# cslr_srio register map
Vendor: Texas Instruments
Peripheral module from a debugger description file (folder TCI6484_C6457).
Registers are 32-bit, access not given, reset 0x0 unless marked. A register's access mark holds for its fields unless they carry their own. Offsets are as the file gives them; lines under a group give offsets from that group; [hi:lo] are bit positions; {n}, {i} and the like mark numbered series; 'fields as' and 'values as' point back to an identical list; <NAME> marks a mode.

## SRIO (part 1 of 2) — Rapid input/output
{0x0+0x10*i} TX_BUFF_DESC[{i}] (i=0..31) group — TX buffer descriptors
  0x00 TXnextDescPtr rw — Transfer buffer descriptor 0
    [31:0] NEXT_DESC — Next Descriptor Pointer - The 32-bit word aligned memory address of the next buffer descriptor in the TX queue. This is the mechanism used to reference the next buffer descriptor from the current buffer descriptor. If the value of this pointer is zero then the current buffer is the last buffer in the queue.
  0x04 TXbuffPtr rw — Transmit buffer descriptor 1
    [31:0] BUFFER_POINTER — Buffer Pointer - The byte aligned memory address of the buffer associated with the buffer descriptor.
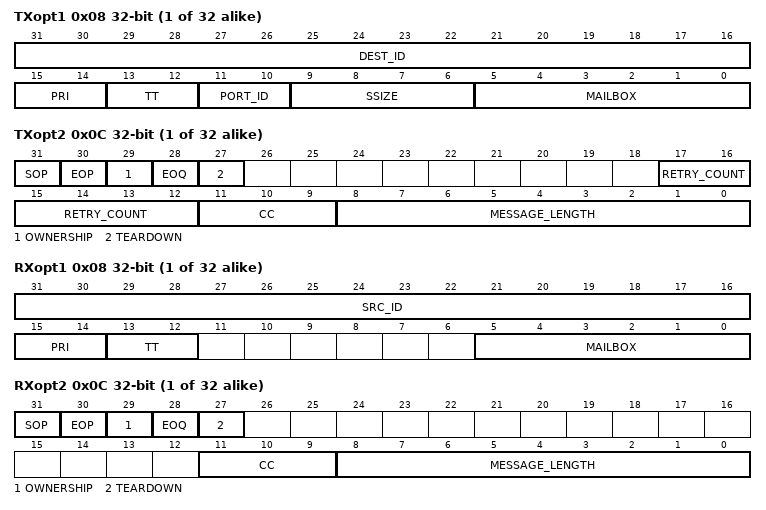
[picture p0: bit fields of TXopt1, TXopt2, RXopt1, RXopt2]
  0x08 TXopt1 rw — Transmit buffer descriptor 2
    [31:16] DEST_ID — Destination Node Id  Unique Node identifier for the Destination of the message
    [15:14] PRI — Message Priority  Specifies the SRIO priority at which the message will be sent. Messages should not be sent at a priority level of 3 since the message response is required to promote the priority to avoid system deadlock. It is the responsibility of the software to assign the appropriate out-going priority
    [13:12] TT — RapidIO tt field specifying 8 or 16bit DeviceIDs
    [11:10] PORT_ID — Port number for routing outgoing packet.
    [9:6] SSIZE — RIO standard message payload size. Indicates how the hardware should segment the out-going message by specifying the maximum number of double-words per packet
    [5:0] MAILBOX — Destination Mailbox  Specifies the mailbox to which the message will be sent.
  0x0C TXopt2 — Transmit buffer descriptor 3
    [31] SOP rw — Start of Message - Indicates that the descriptor buffer is the first buffer in the message
    [30] EOP rw — End of Message - Indicates that the descriptor buffer is the last buffer in the message
    [29] OWNERSHIP rw — Ownership - Indicates ownership of the message and is valid only on sop. This bit is set by the host and cleared by the port when the message has been transmitted. The host uses this bit to reclaim buffers
    [28] EOQ rw — End Of Queue - Set by the port to indicate that all messages in the queue have been transmitted and the TX queue is empty. End of queue is determined by the port when the next_descriptor_pointer is zero on an eop buffer. This bit is valid only on eop
    [27] TEARDOWN rw — Teardown Complete  Set by the port to indicate that the host commanded teardown process is complete, and the channel buffers may be reclaimed by the host.
    [17:12] RETRY_COUNT rw — Message Retry Count  Set by the cpu to indicate the total number of retries allowed for this message, including all segments. Decremented by the port each time a message is retried
    [11:9] CC rw — Completion Code
    [8:0] MESSAGE_LENGTH rw — Message Length  Written by the CPU to specify the number of double-words to transmit. Message payloads are limited to a maximum size of 512 double-words (4096bytes).
{0x0+0x10*i} RX_BUFF_DESC[{i}] (i=0..31) group — RX buffer descriptors
  0x00 RXnextDescPtr rw — Receive buffer descriptor 0
    [31:0] NEXT_DESC — Next Descriptor Pointer - The 32-bit word aligned memory address of the next buffer descriptor in the RX queue. This is the mechanism used to reference the next buffer descriptor from the current buffer descriptor. If the value of this pointer is zero then the current buffer is the last buffer in the queue.
  0x04 RXbuffPtr rw — Receive buffer descriptor 1
    fields as TX_BUFF_DESC[0].TXbuffPtr
  0x08 RXopt1 — Receive buffer descriptor 2
    [31:16] SRC_ID rw — Source Node Id  Unique Node identifier for the Source of the message
    [15:14] PRI rw — Message Priority  Specifies the SRIO priority at which the message will be sent. Messages should not be sent at a priority level of 3 since the message response is required to promote the priority to avoid system deadlock. It is the responsibility of the software to assign the appropriate out-going priority
    [13:12] TT rw — RapidIO tt field specifying 8 or 16bit DeviceIDs
    [5:0] MAILBOX rw — Destination Mailbox  Specifies the mailbox to which the message was sent.
  0x0C RXopt2 — Receive buffer descriptor 3
    [31] SOP rw — Start of Message - Indicates that the descriptor buffer is the first buffer in the message
    [30] EOP rw — End of Message - Indicates that the descriptor buffer is the last buffer in the message
    [29] OWNERSHIP rw — Ownership - Indicates ownership of the message and is valid only on "sop". This bit is set by the host and cleared by the port when the message has been transmitted. The host uses this bit to reclaim buffers
    [28] EOQ rw — End Of Queue - Set by the port to indicate that the RX queue empty condition exists. This bit is valid only on "eop". The port determines the end of queue condition by a zero next_descriptor_pointer
    [27] TEARDOWN rw — Teardown Complete  Set by the port to indicate that the host commanded teardown process is complete, and the channel buffers may be reclaimed by the host.
    [11:9] CC rw — Completion Code
    [8:0] MESSAGE_LENGTH rw — Message Length  Written by the CPU to specify the number of double-words to transmit. Message payloads are limited to a maximum size of 512 double-words (4096bytes).
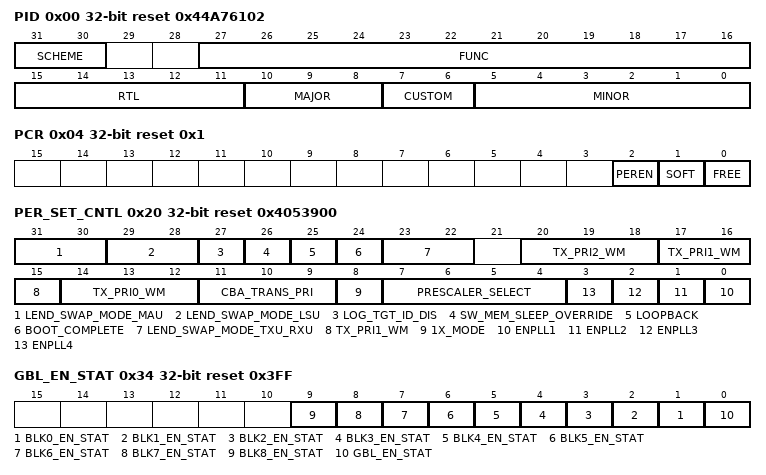
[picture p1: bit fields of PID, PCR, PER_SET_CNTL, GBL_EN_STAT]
0x00 PID reset 0x44A76102 — Peripheral Identification Register
  [31:30] SCHEME ro, [27:16] FUNC ro, [15:11] RTL ro, [10:8] MAJOR ro, [7:6] CUSTOM ro, [5:0] MINOR ro
0x04 PCR reset 0x1 — Peripheral Control register
  [2] PEREN rw — Peripheral Enable. Control the flow of data in the logical layer of the peripheral. As an initiator, it will prevent TX transaction generation and as a target, it will disable incoming requests. This should be the last enable bit to toggle when bringing the device out of reset to begin normal operation
    0=DISABLE (Disables data flow control); 1=ENABLE (Enables data flow control)
  [1] SOFT rw — Emulation Control  SOFT bit
  [0] FREE rw — Emulation Control  FREE bit
0x20 PER_SET_CNTL reset 0x4053900 — Peripheral Settings Control register
  [31:30] LEND_SWAP_MODE_MAU rw — MAU little-endian swapping mode
    0=MODE_A (MAU little-endian swapping mode); 1=MODE_B (MAU little-endian swapping mode); 2=MODE_C (MAU little-endian swapping mode); 3=MODE_D (MAU little-endian swapping mode)
  [29:28] LEND_SWAP_MODE_LSU rw — LSU little-endian swapping mode
    0=MODE_A (LSU little-endian swapping mode); 1=MODE_B (LSU little-endian swapping mode); 2=MODE_C (LSU little-endian swapping mode); 3=MODE_D (LSU little-endian swapping mode)
  [27] LOG_TGT_ID_DIS rw — Logical layer disable. This bit disables all the packet types at the logical layer.
    0=DESTROY_PACKETS (All non-matching packets are destroyed.); 1=FORWARD_PACKETS (All packets, regardless of the destination ID, are forwarded to the application.)
  [26] SW_MEM_SLEEP_OVERRIDE rw — Software Memory Sleep Override 0b0  While in shutdown, memories are put in sleep mode 0b1  While in shutdown, memories are not put in sleep mode
    0=DISABLE; 1=ENABLE (Memories are not put in sleep mode)
  [25] LOOPBACK rw — Loopback mode. 0b: Normal operation 1b: Loop back. Trasmit data to receive on the same port.Packet data is looped back in the digital domain before the SerDes macros
    0=DISABLE (Normal operation); 1=ENABLE (Loop back mode)
  [24] BOOT_COMPLETE rw — Controls ability to write any register during initialization. It also includes read only registers during normal mode of operation, that have application defined reset value. 0  write enabled 1 - write to read only registers disabled Usually the boot_complete is asserted once after reset to define power on configuration
    0=WRITE_ENABLE (Write to read only registers enabled); 1=WRITE_DISABLE (Write to read only registers disabled)
  [23:22] LEND_SWAP_MODE_TXU_RXU rw — TXU/RXU little-endian swapping mode
    0=MODE_A; 1=MODE_B; 2=MODE_C; 3=MODE_D
  [20:18] TX_PRI2_WM rw — Transmit credit threshold. Sets the required number of logical layer TX buffers needed to send prority 2 packets across the UDI interface. This is valid for all ports in 1X mode only
  [17:15] TX_PRI1_WM rw — Transmit credit threshold. Sets the required number of logical layer TX buffers needed to send prority 1 packets across the UDI interface. This is valid for all ports in 1X mode only
  [14:12] TX_PRI0_WM rw — Transmit credit threshold. Sets the required number of logical layer TX buffers needed to send prority 0 packets across the UDI interface. This is valid for all ports in 1X mode only
  [11:9] CBA_TRANS_PRI rw — VBUS transaction priority. 0b000  Highest Priority, 0b111  Lowest Priority.
  [8] 1X_MODE rw — This register bit determines the UDI buffering setup(Prority versus Port).
    0=DISABLE (UDI buffers are priority based); 1=ENABLE (UDI buffers are port based. This mode must be selected when using more than one 1X port)
  [7:4] PRESCALER_SELECT rw — Internal frequency prescaler, used to drive the request to response timers. These 4 bits are the prescaler reload value allowing division of the VBUS clock by a range from 1 up to 16. Setting should reflect the device VBUS frequency.
  [n-1] ENPLL{n} rw (n=1..4) — Drives SerDes Macro {n} PLL Enable signal
0x30 GBL_EN — Peripheral Global Enable register
  [0] EN rw — Controls reset to all clock domains within the peripheral
    0=DISABLE (Peripheral to be disabled (held in reset, clocks disabled)); 1=ENABLE (Peripheral to be enabled)
0x34 GBL_EN_STAT reset 0x3FF — Peripheral Global Enable Status
  [n+1] BLK{n}_EN_STAT ro (n=0..8) — Indicates state of BLK{n}_EN reset signal
  [0] GBL_EN_STAT ro — Indicates state of GBL_EN reset signal
{0x38+8i} BLK{i}_EN reset 0x1 (i=0..8) — Block Enable
  [0] EN rw — Controls reset to Logical block n (0 to 8)
    0=DISABLE (Logical block n disabled); 1=ENABLE (Logical block n enabled)
{0x3C+8i} BLK{i}_EN_STAT reset 0x1 (i=0..8) — Block Enable Status
  [0] EN_STAT rw — Indicates state of BLKn_EN reset signal 0 Logical block n disabled, in reset and clock is off 1 Logical block n enabled and clocking
    values as BLK0_EN.EN
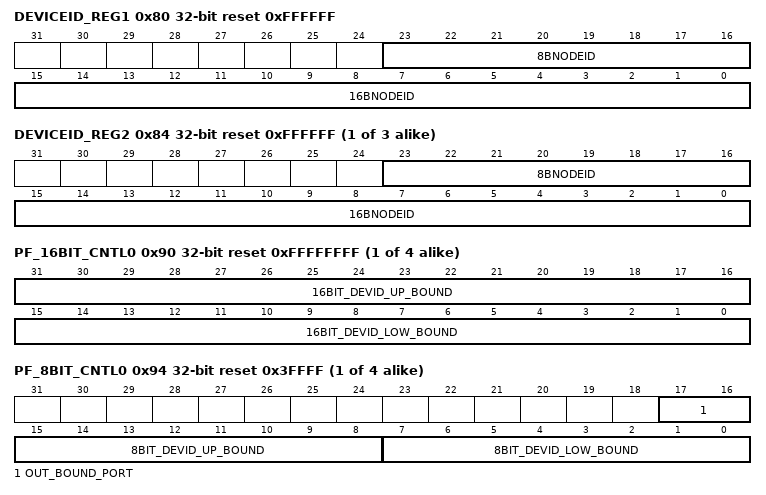
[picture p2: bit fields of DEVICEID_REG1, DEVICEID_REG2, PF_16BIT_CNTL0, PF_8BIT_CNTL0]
0x80 DEVICEID_REG1 reset 0xFFFFFF — RapidIO DEVICEID1 Register
  [23:16] 8BNODEID rw — This value is equal to the value of the RapidIO Base Device ID CSR. The CPU must read the CSR value and set this register, so that out-going packets contain the correct SOURCEID value
  [15:0] 16BNODEID rw — This value is equal to the value of the RapidIO Base Device ID CSR. The CPU must read the CSR value and set this register, so that out-going packets contain the correct SOURCEID value
{0x7C+4i} DEVICEID_REG{i} reset 0xFFFFFF (i=2..4) — RapidIO DEVICEID{i} Register
  [23:16] 8BNODEID rw — This is a secondary supported DeviceID checked against an in-coming packet's DestID field. Typically used for Multi-cast support
  [15:0] 16BNODEID rw — This is a secondary supported DeviceID checked against an in-coming packet's DestID field. Typically used for Multi-cast support
{0x90+8i} PF_16BIT_CNTL{i} rw reset 0xFFFFFFFF (i=0..3) — Packet Forwarding register for 16b DeviceIDs
  [31:16] 16BIT_DEVID_UP_BOUND — Upper 16b DeviceID boundary. DestID above this range cannot use the table entry
  [15:0] 16BIT_DEVID_LOW_BOUND — Lower 16b DeviceID boundary. DestID lower than this number cannot use the table entry
{0x94+8i} PF_8BIT_CNTL{i} reset 0x3FFFF (i=0..3) — Packet Forwarding register for 8b DeviceIDs
  [17:16] OUT_BOUND_PORT rw — Output port number for packet's whose DestID falls within the 8b or 16b range for this table entry
  [15:8] 8BIT_DEVID_UP_BOUND rw — Upper 8b DeviceID boundary. DestID above this range cannot use the table entry
  [7:0] 8BIT_DEVID_LOW_BOUND rw — Lower 8b DeviceID boundary. DestID lower than this number cannot use the table entry
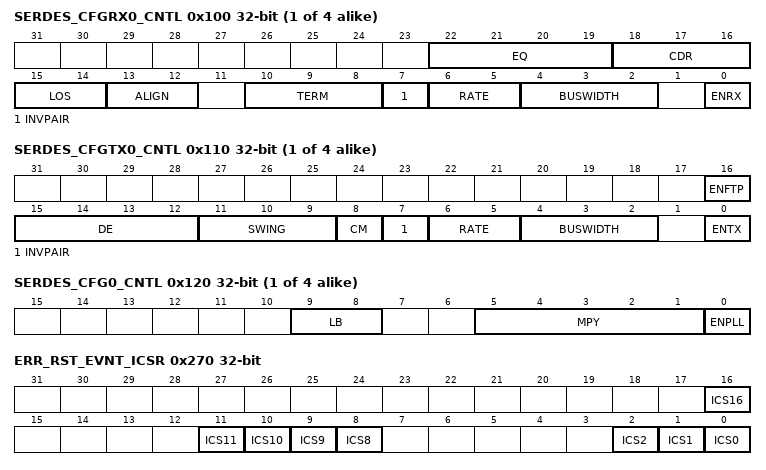
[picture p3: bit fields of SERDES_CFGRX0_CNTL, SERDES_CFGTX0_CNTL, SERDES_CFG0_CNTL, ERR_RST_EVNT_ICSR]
{0x100+4i} SERDES_CFGRX{i}_CNTL (i=0..3) — SerDes RX Channels CFG register
  [22:19] EQ rw — Equalizer. Enables and configures the adaptive equalizer to compensate for loss in the transmission media.
  [18:16] CDR rw — Clock/data recovery. Configures the clock/data recovery algorithm.
  [15:14] LOS rw — Loss of signal. Enables loss of signal detection with 2 selectable thresholds.
  [13:12] ALIGN rw — Symbol alignment. Enables internal or external symbol alignment.
  [10:8] TERM rw — Termination. Selects input termination options suitable for a variety of AC or DC coupled scenarios.
  [7] INVPAIR rw — Invert polarity. Inverts polarity of RXPi and RXNi.
  [6:5] RATE rw — Operating rate. Selects full, half, quarter rate operation
  [4:2] BUSWIDTH rw — Bus width. Selects the parallel interface width (10 or 8 bit).
  [0] ENRX rw — Receive enable.
{0x110+4i} SERDES_CFGTX{i}_CNTL (i=0..3) — SerDes TX Channels CFG register
  [16] ENFTP rw — Enable fixed TXBCLKINn phase.
  [15:12] DE rw — De-emphasis. Selects one of 15 output de-emphasis settings from 4.76% to 71.42%.
  [11:9] SWING rw — Output swing. Selects one of 8 output amplitude settings between 125 and 1250mVdfpp.
  [8] CM rw — Common mode. Adjusts the common mode to suit the termination at the attached receiver.
  [7] INVPAIR rw — Invert polarity. Inverts polarity of TXPn and TXNn.
  [6:5] RATE rw — Operating rate. Selects full, half, quarter rate operation
  [4:2] BUSWIDTH rw — Bus width. Selects the parallel interface width (10 or 8 bit).
  [0] ENTX rw — Trasmit enable.
{0x120+4i} SERDES_CFG{i}_CNTL (i=0..3) — SerDes Macros CFG register
  [9:8] LB rw — Loop Bandwidth. Specify loop bandwidth settings.
  [5:1] MPY rw — PLL multiply. Select PLL Multiply factors between 4 and 60.
  [0] ENPLL rw — Enable PLL. Enables the PLL.
{0x200+0x10*i} DOORBELL_ICSR{i} (i=0..3) — DOORBELL Interrupt Status register
  [15:0] ICS[16] rw — Doorbell n (0 to 3) interrupt condition status bits
{0x208+0x10*i} DOORBELL_ICCR{i} (i=0..3) — DOORBELL Interrupt Clear register
  [15:0] ICC[16] wo — Doorbell n (0 to 3) interrupt clear bits
    1=CLEAR
0x240 RX_CPPI_ICSR — RX CPPI Interrupt Status register
  [15:0] ICS[16] rw — RX CPPI Interrupt, Buffer descriptor Queue 0 to 15
0x248 RX_CPPI_ICCR — RX CPPI Interrupt Clear register
  [15:0] ICC[16] wo — RX CPPI Interrupt clear, Buffer descriptor Queue 0 to 15
    1=CLEAR
0x250 TX_CPPI_ICSR — TX CPPI Interrupt Status register
  [15:0] ICS[16] rw — TX CPPI Interrupt, Buffer descriptor Queue 0 to 15
0x258 TX_CPPI_ICCR — TX CPPI Interrupt Clear register
  [15:0] ICC[16] wo — TX CPPI Interrupt clear, Buffer descriptor Queue 0 to 15
    1=CLEAR
0x260 LSU_ICSR ro — LSU Status Interrupt register
  [31:0] ICS[32] — Load/Store module interrupt condition status bits
0x268 LSU _ICCR wo — LSU Clear Interrupt register
  [31:0] ICC[32] — Load/Store module interrupt clear bits
    1=CLEAR
0x270 ERR_RST_EVNT_ICSR — Error, Reset, and Special Event Status Interrupt register
  [16] ICS16 ro — Device Reset Interrupt from any port
  [n] ICS{n} ro (n=8..11) — Port{n-8} Error
  [2] ICS2 ro — Logical Layer Error Management Event Capture
  [1] ICS1 ro — Port-write-In request received on any port
  [0] ICS0 ro — Multi-cast event control symbol interrupt received on any port
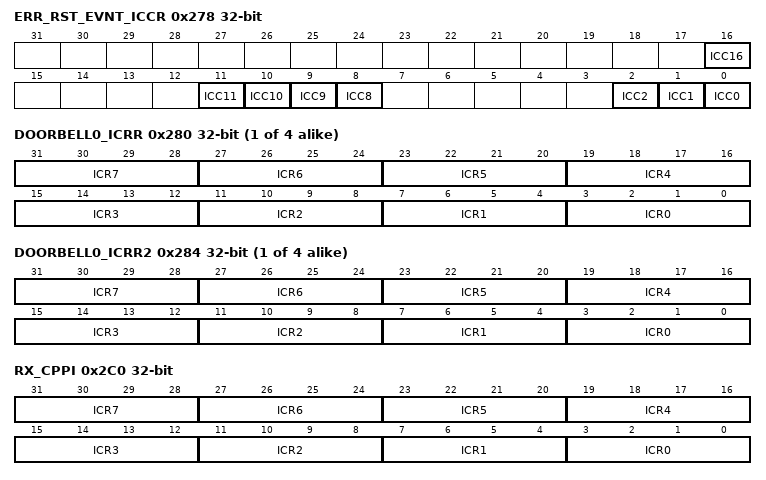
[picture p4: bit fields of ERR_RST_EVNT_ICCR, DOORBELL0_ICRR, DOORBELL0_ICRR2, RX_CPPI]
0x278 ERR_RST_EVNT_ICCR — Error, Reset, and Special Event Clear Interrupt register
  [16] ICC16 wo — Device Reset Interrupt from any port
  [n] ICC{n} wo (n=8..11) — Port{n-8} Error
  [2] ICC2 wo — Logical Layer Error Management Event Capture
  [1] ICC1 wo — Port-write-In request received on any port
  [0] ICC0 wo — Multi-cast event control symbol interrupt received on any port
{0x280+0x10*i} DOORBELL{i}_ICRR rw (i=0..3) — DOORBELL Interrupt Condition Routing register (bits 0 to 7)
  [4n+3:4n] ICR{n} (n=0..7)
{0x284+0x10*i} DOORBELL{i}_ICRR2 rw (i=0..3) — DOORBELL Interrupt Condition Routing register (bits 8 to 15)
  [4n+3:4n] ICR{n} (n=0..7)
0x2C0 RX_CPPI _ICRR rw — RX CPPI Interrupt Condition Routing register (bits 0 to 7)
  [4n+3:4n] ICR{n} (n=0..7)
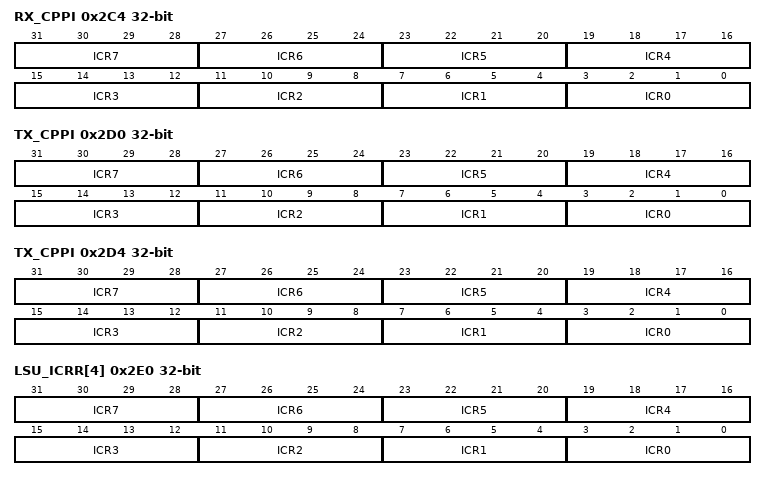
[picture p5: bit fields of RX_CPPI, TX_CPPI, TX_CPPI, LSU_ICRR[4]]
0x2C4 RX_CPPI _ICRR2 rw — RX CPPI Interrupt Condition Routing register (bits 8 to 15)
  [4n+3:4n] ICR{n} (n=0..7)
0x2D0 TX_CPPI _ICRR rw — TX CPPI Interrupt Condition Routing register (bits 0 to 7)
  [4n+3:4n] ICR{n} (n=0..7)
0x2D4 TX_CPPI _ICRR2 rw — TX CPPI Interrupt Condition Routing register (bits 8 to 15)
  [4n+3:4n] ICR{n} (n=0..7)
0x2E0 LSU_ICRR[4] rw — LSU Module Interrupt Condition Routing register
  [4n+3:4n] ICR{n} (n=0..7)
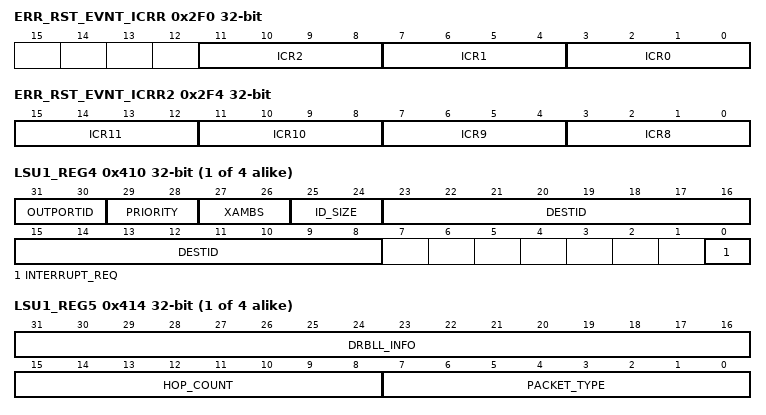
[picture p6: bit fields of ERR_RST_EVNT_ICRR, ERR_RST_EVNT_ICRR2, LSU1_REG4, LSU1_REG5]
0x2F0 ERR_RST_EVNT_ICRR — Err/Reset/special event Interrupt Condition Routing register
  [11:8] ICR2 rw — Logical Layer Error Management Event Capture routing
  [7:4] ICR1 rw — Routing of Port-write-In request received on any port
  [3:0] ICR0 rw — Routing of Multi-cast event control symbol interrupt received on any port
0x2F4 ERR_RST_EVNT_ICRR2 — Err/Reset/special event Interrupt Condition Routing register
  [4n-29:4n-32] ICR{n} rw (n=8..11) — Port{n-8} Error routing
0x2F8 ERR_RST_EVNT_ICRR3 — Err/Reset/special event Interrupt Condition Routing register
  [3:0] ICR16 rw — Routing of Device Reset Interrupt from any port
0x300 INTDST_DECODE[8] ro — INTDST Interrupt Status Decode registers
  [31:0] ISDR[32] — Interrupt sources that select a particular physical interrupt destination, are mapped to specific bits in the decode register. The interrupt sources are mapped to an interrupt decode register, only if the ICRR routes the interrupt source to the corresponding physical interrupt. The status decode bit is a logical "OR" of multiple interrupt sources that are mapped to the same bit.
0x320 INTDST_RATE_CNTL[8] rw — INTDST Interrupt Rate Control registers
  [31:0] COUNT_DOWN_VALUE — The rate at which an interrupt can be generated is controllable for each physical interrupt destination. Rate control is implemented with a programmable down-counter. The counter re-loads and immediately starts down-counting each time the CPU writes these registers. Once the rate control counter register is written, and the counter value reaches zero (note the CPU may write zero immediately for a zero count), the interrupt pulse generation logic is allowed to fire a single pulse if any bits in the corresponding ICSR register bits are set (or become set after the zero count is reached). .
{0x3E0+0x20*i} LSU{i}_REG0 rw (i=1..4) — LSU Control register0
  [31:0] ADDRESS_MSB — 32 bit Ext address fields
{0x3E4+0x20*i} LSU{i}_REG1 rw (i=1..4) — LSU Control register1
  [31:0] ADDRESS_LSB_CONFIG_OFFSET — 1) 32b Address  Packet Types 2,5, and 6 (Will be used in conjunction with BYTE_COUNT to create 64b aligned RapidIO packet header address) 2) 24b Config_offset Field  Maintenance Packets Type 8 (Will be used in conjunction with BYTE_COUNT to create 64b aligned RapidIO packet header Config_offset); The 2 lsb of this field must be zero since the smallest configuration access is 4B.
{0x3E8+0x20*i} LSU{i}_REG2 rw (i=1..4) — LSU Control register2
  [31:0] DSP_ADDRESS — 32b DSP byte address
{0x3EC+0x20*i} LSU{i}_REG3 (i=1..4) — LSU Control register3
  [11:0] BYTE_COUNT rw — Number of data bytes to Read/Write - up to 4KB. (Used in conjunction with RapidIO address to create WRSIZE/RDSIZE and WDPTR in RapidIO packet header).
{0x3F0+0x20*i} LSU{i}_REG4 (i=1..4) — LSU Control register4
  [31:30] OUTPORTID rw — Not applicable for Rapid IO header. Indicates the output port number for the packet to be transmitted from. Specified by the CPU along with NodeID.
  [29:28] PRIORITY rw — RapidIO prio field specifying packet priority. Request packets should not be sent at a priority level of 3 in order to avoid system deadlock. It is the responsibility of the software to assign the appropriate out-going priority.
  [27:26] XAMBS rw — RapidIO xambs field specifying extended address MSB
  [25:24] ID_SIZE rw — RapidIO tt field specifying 8 or 16bit DeviceIDs
    0=8BIT (8 bit device Ids); 1=16BIT (16 bit device Ids)
  [23:8] DESTID rw — RapidIO destinationID field specifying target device
  [0] INTERRUPT_REQ rw — CPU controlled request bit used for interrupt generation. Typically used in conjunction with non-posted commands to alert the CPU when the requested data/status is present. 0b0 - An interrupt is not requested upon completion of command 0b1- An interrupt is requested upon completion of command
    0=DISABLE (Interrupt is not requested); 1=ENABLE (Interrupt is requested)
{0x3F4+0x20*i} LSU{i}_REG5 rw (i=1..4) — LSU Control register5
  [31:16] DRBLL_INFO — RapidIO doorbell info field for type 10 packets
  [15:8] HOP_COUNT — RapidIO hop_count field specified for Type 8 Maintenance packets
  [7:0] PACKET_TYPE — 4 msb = 4b ftype field for all packets and 4 lsb = 4b trans field for Packet types 2,5,8
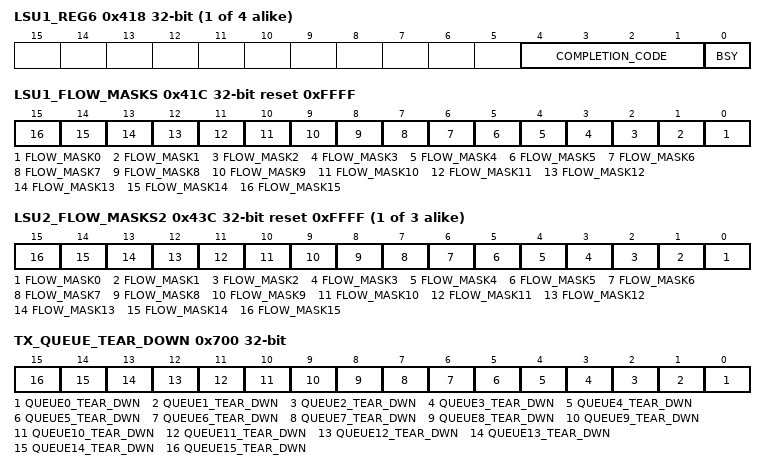
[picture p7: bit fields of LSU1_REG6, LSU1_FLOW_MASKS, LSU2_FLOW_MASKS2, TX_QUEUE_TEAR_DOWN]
{0x3F8+0x20*i} LSU{i}_REG6 (i=1..4) — LSU Control register6
  [4:1] COMPLETION_CODE ro — Indicates the status of the pending command 0b000  Transaction complete, No Errors (Posted/Non-posted) 0b001  Transaction Timeout occurred on Non-posted transaction 0b010  Transaction complete, Packet not sent due to flow control blockade (Xoff) 0b011  Transaction complete, Non-posted response packet (type 8 and 13) contained ERROR status, or response payload length was in error 0b100  Transaction complete, Packet not sent due to unsupported transaction type or invalid programming encoding for one or more LSU register fields 0b101  DMA data transfer error 0b110  "Retry" DOORBELL response received, or Atomic Test-and-swap was not allowed (semaphore in use) 0b111  Transaction complete, Packet not sent due to unavailable outbound credit at given priority
  [0] BSY ro — Indicates status of the command registers 0b0 - Command registers are available(writable) for next set of transfer descriptors 0b1 - Command registers are busy with current transfer
0x41C LSU1_FLOW_MASKS reset 0xFFFF — Core n LSU Congestion Control Flow Mask
  [n] FLOW_MASK{n} rw (n=0..15)
{0x3FC+0x20*i} LSU{i}_FLOW_MASKS{i} reset 0xFFFF (i=2..4) — Core n LSU Congestion Control Flow Mask
  [n] FLOW_MASK{n} rw (n=0..15)
0x500 QUEUE_TXDMA_HDP[16] rw — Queue TX DMA Head Descriptor Pointer
  [31:0] TX_HDP — This field is the host memory address for the first buffer descriptor in the transmit queue. This field is written by the host to initiate queue transmit operations and is zeroed by the port when all packets in the queue have been transmitted. An error condition results if the host writes this field when the current field value is nonzero. The address must be 32-bit word aligned
0x580 QUEUE_TXDMA_CP[16] rw — Queue TX DMA Completion Pointer
  [31:0] TX_CP — This field is the host memory address for the transmit queue completion pointer. This register is written by the host with the buffer descriptor address for the last buffer processed by the host during interrupt processing. The port uses the value written to determine if the interrupt should be deasserted.
0x600 QUEUE_RXDMA_HDP[16] rw — Queue RX DMA Head Descriptor Pointer
  [31:0] RX_HDP — Rx Queue Head Descriptor Pointer: This field is the host memory address for the first buffer descriptor in the channel receive queue. This field is written by the host to initiate queue receive operations and is zeroed by the port when all free buffers have been used. An error condition results if the host writes this field when the current field value is nonzero. The address must be 32-bit word aligned.
0x680 QUEUE_RXDMA_CP[16] rw — Queue RX DMA Completion Pointer
  [31:0] RX_CP — Rx Queue Completion Pointer: This field is the host memory address for the receive queue completion pointer. This register is written by the host with the buffer descriptor address for the last buffer processed by the host during interrupt processing. The port uses the value written to determine if the interrupt should be deasserted
0x700 TX_QUEUE_TEAR_DOWN
  [n] QUEUE{n}_TEAR_DWN wo (n=0..15) — Write = 1, tear down of Queue {n}
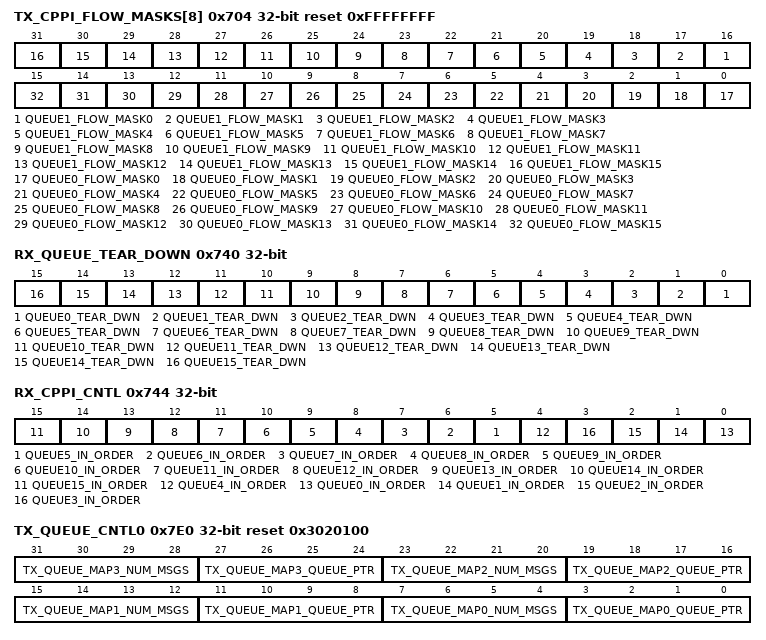
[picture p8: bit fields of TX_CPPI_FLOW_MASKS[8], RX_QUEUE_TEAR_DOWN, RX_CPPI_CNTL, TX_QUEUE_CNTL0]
0x704 TX_CPPI_FLOW_MASKS[8] rw reset 0xFFFFFFFF — TX CPPI Supported Flow Mask
  [n+16] QUEUE1_FLOW_MASK{n} (n=0..15) — Flow mask queue 1 0b0  TX source doesn't support Flow n (0 to 15) from table entry for QUEUE1 0b1  TX source does support Flow n ( 0 to 15) from table entry for QUEUE1
  [n] QUEUE0_FLOW_MASK{n} (n=0..15) — Flow mask queue 0 0b0  TX source doesn't support Flow n (0 to 15) from table entry for QUEUE0 0b1  TX source does support Flow n ( 0 to 15) from table entry for QUEUE0
0x740 RX_QUEUE_TEAR_DOWN
  fields as TX_QUEUE_TEAR_DOWN
0x744 RX_CPPI_CNTL — RX CPPI Control register
  [n] QUEUE{n}_IN_ORDER rw (n=5..15) — 0b0  allows out-of-order message 0b1- only allows in-order messages. Used for applications with dedicated source-destination flows
  [4] QUEUE4_IN_ORDER rw — 0b0  allows out-of-order message 0b1- only allows in-order messages Used for applications with dedicated source-destination flows
  [n] QUEUE{n}_IN_ORDER rw (n=0..3) — 0b0  allows out-of-order message 0b1- only allows in-order messages. Used for applications with dedicated source-destination flows
0x7E0 TX_QUEUE_CNTL0 rw reset 0x3020100 — TX CPPI Weighted Round Robin Control
  [8n+7:8n+4] TX_QUEUE_MAP{n}_NUM_MSGS (n=0..3) — Number of contiguous messages (descriptors) to process before moving to TX_Queue_Map{n+1}
  [8n+3:8n] TX_QUEUE_MAP{n}_QUEUE_PTR (n=0..3) — Pointer to a Queue, programmable to any of the 16 TX queues
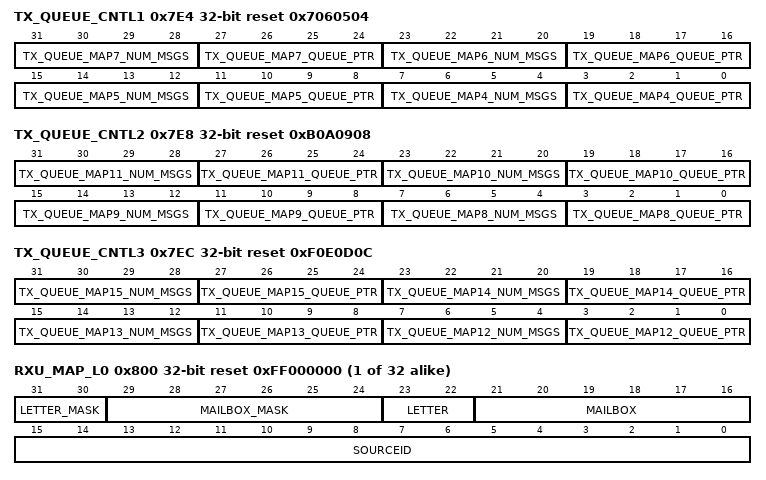
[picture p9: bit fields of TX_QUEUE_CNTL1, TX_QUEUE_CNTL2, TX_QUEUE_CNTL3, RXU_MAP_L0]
0x7E4 TX_QUEUE_CNTL1 rw reset 0x7060504 — TX CPPI Weighted Round Robin Control
  [8n-25:8n-28] TX_QUEUE_MAP{n}_NUM_MSGS (n=4..7) — Number of contiguous messages (descriptors) to process before moving to TX_Queue_Map{n+1}
  [8n-29:8n-32] TX_QUEUE_MAP{n}_QUEUE_PTR (n=4..7) — Pointer to a Queue, programmable to any of the 16 TX queues
0x7E8 TX_QUEUE_CNTL2 rw reset 0xB0A0908 — TX CPPI Weighted Round Robin Control
  [8n-57:8n-60] TX_QUEUE_MAP{n}_NUM_MSGS (n=8..11) — Number of contiguous messages (descriptors) to process before moving to TX_Queue_Map{n+1}
  [8n-61:8n-64] TX_QUEUE_MAP{n}_QUEUE_PTR (n=8..11) — Pointer to a Queue, programmable to any of the 16 TX queues
0x7EC TX_QUEUE_CNTL3 rw reset 0xF0E0D0C — TX CPPI Weighted Round Robin Control
  [31:28] TX_QUEUE_MAP15_NUM_MSGS — Number of contiguous messages (descriptors) to process before moving to TX_Queue_Map0
  [8n-93:8n-96] TX_QUEUE_MAP{n}_QUEUE_PTR (n=12..15) — Pointer to a Queue, programmable to any of the 16 TX queues
  [23:20] TX_QUEUE_MAP14_NUM_MSGS — Number of contiguous messages (descriptors) to process before moving to TX_Queue_Map15
  [15:12] TX_QUEUE_MAP13_NUM_MSGS — Number of contiguous messages (descriptors) to process before moving to TX_Queue_Map14
  [7:4] TX_QUEUE_MAP12_NUM_MSGS — Number of contiguous messages (descriptors) to process before moving to TX_Queue_Map13
{0x800+8i} RXU_MAP_L{i} rw reset 0xFF000000 (i=0..31) — MailBox-to-queue mapping register
  [31:30] LETTER_MASK — Allowed letter mask for this mapping register
  [29:24] MAILBOX_MASK — Allowed mail box mask for this mapping register
  [23:22] LETTER — Allowed letter for this mapping register
  [21:16] MAILBOX — Allowed mail box for this mapping register
  [15:0] SOURCEID — The SOURCEID field is used to indicate which external device has access to the mapping entry and corresponding queue. A compare is performed between the sourceID of the incoming message packet and each relevant mailbox/letter table mapping entry SOURCEID field. A mis-compare results in an ERROR response back to the sender and the transaction is logged in the Logical Layer Error Management capture registers
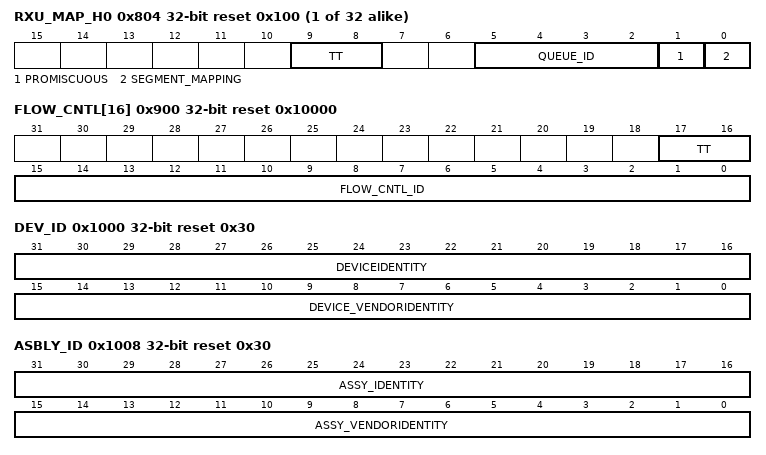
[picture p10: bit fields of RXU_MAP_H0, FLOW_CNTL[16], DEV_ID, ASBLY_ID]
{0x804+8i} RXU_MAP_H{i} reset 0x100 (i=0..31) — MailBox-to-queue mapping register
  [9:8] TT rw — Transport type 0b0: matches the 8 LSB of the source ID 0b1: matches the full 16 bits of the source ID
    0=MATCH_8BIT_SRCID (matches the 8 LSB of the source ID); 1=MATCH_16BIT_SRCID (matches the full 16 bits of the source ID)
  [5:2] QUEUE_ID rw — Corresponding queue 0 to queue 15
  [1] PROMISCUOUS rw — Promiscuous =1, full access to the queue for any source ID
    0=DISABLE (Promiscuous bit disabled); 1=ENABLE (Promiscuous bit enabled)
  [0] SEGMENT_MAPPING rw — Segment mapping 0b0  single segment (all six bits of mailbox valid ) 0b1  Multi segment(only 2 LSBs of Mailbox valid )
    0=SINGLE_SEGMENT (all six bits of mailbox valid); 1=MULTI_SEGMENT (only 2 LSBs of Mailbox valid)
0x900 FLOW_CNTL[16] reset 0x10000 — Flow Control Table Entry Registers
  [17:16] TT rw — Selects Flow_Cntl_ID length. 0b00  8b Ids 0b01  16b Ids 0b10  0b11 - reserved
    0=8BIT_ID (8 bit Ids); 1=16BIT_ID (16 bit Ids)
  [15:0] FLOW_CNTL_ID rw — DestID of Flow n
0x1000 DEV_ID ro reset 0x30 — Device Identity CAR
  [31:16] DEVICEIDENTITY — Identifies the type of device. Vendor specific
  [15:0] DEVICE_VENDORIDENTITY — Device Vendor ID assigned by RapidIO TA
0x1004 DEV_INFO ro — Device Information CAR
  [31:0] DEVICEREV — Vendor supply device revision
0x1008 ASBLY_ID ro reset 0x30 — Assembly Identity CAR
  [31:16] ASSY_IDENTITY — Assembly Identifier. Vendor Specific
  [15:0] ASSY_VENDORIDENTITY — Assembly Vendor Identifier assigned by RapidIO TA.
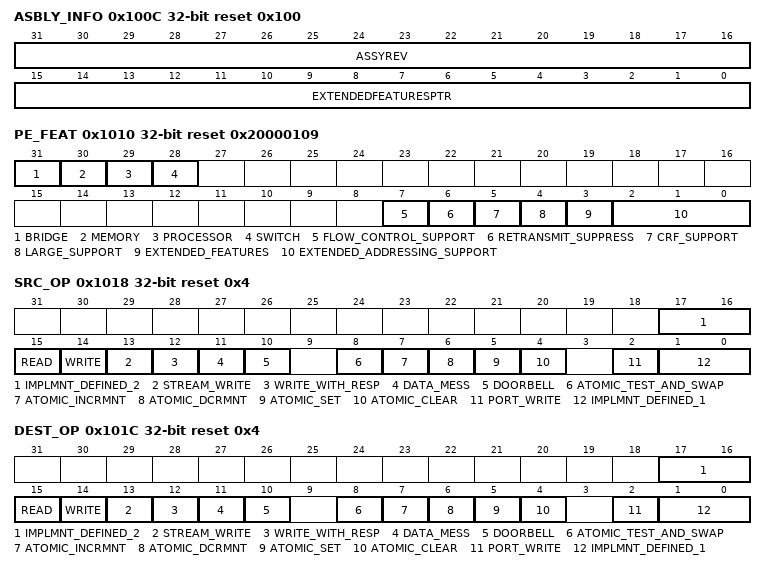
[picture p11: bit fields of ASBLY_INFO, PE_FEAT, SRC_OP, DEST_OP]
0x100C ASBLY_INFO ro reset 0x100 — Assembly Information CAR
  [31:16] ASSYREV — Assembly revision level
  [15:0] EXTENDEDFEATURESPTR — Pointer to first entry in extended features list
0x1010 PE_FEAT reset 0x20000109 — Processing Element Features CAR
  [31] BRIDGE ro — PE can bridge to another interface. Examples are PCI, proprietary processor buses, DRAM, etc.
  [30] MEMORY ro — PE has physically addressable local address space and can be accessed as an end point through non-maintenance (i.e. non-coherent read and write) operations. This local address space may be limited to local configuration registers, or could be on-chip SRAM, etc.
  [29] PROCESSOR ro — PE physically contains a local processor or similar device that executes code. A device that bridges to an interface that connects to a processor does not count
  [28] SWITCH ro — PE can bridge to another external RapidIO interface - an internal port to a local end point does not count as a switch port. For example, a device with two RapidIO ports and a local end point is a two port switch, not a three port switch, regardless of the internal architecture
  [7] FLOW_CONTROL_SUPPORT ro — PE supports congestion flow control mechanism 0b1  PE supports flow control
  [6] RETRANSMIT_SUPPRESS ro — PE supports suppression of error recovery on packet CRC errors.0b1  PE supports suppression
  [5] CRF_SUPPORT ro — This bit indicates PE support for the Critical Request Flow (CRF) Function 0b1  PE supports CRF Function
  [4] LARGE_SUPPORT ro — Support of common transport large systems. 0b0  PE does not support common transport large systems 0b1  PE supports common transport large systems
  [3] EXTENDED_FEATURES ro — PE has extended features list; the extended features pointer is valid
  [2:0] EXTENDED_ADDRESSING_SUPPORT ro — Indicates the number address bits supported by the PE both as a source and target of an operation. All PEs shall at minimum support 34 bit addresses. 0b111 - PE supports 66, 50 and 34 bit addresses 0b101 - PE supports 66 and 34 bit addresses 0b011 - PE supports 50 and 34 bit addresses 0b001 - PE supports 34 bit addresses All other encodings reserved
0x1018 SRC_OP reset 0x4 — Source Operations CAR
  [17:16] IMPLMNT_DEFINED_2 ro — Defined by the device implementation
  [15] READ ro — PE can support a read operation
  [14] WRITE ro — PE can support a write operation
  [13] STREAM_WRITE ro — PE can support a streaming-write operation
  [12] WRITE_WITH_RESP ro — PE can support a write-with-response operation
  [11] DATA_MESS ro — PE can support a data message operation
  [10] DOORBELL ro — PE can support a doorbell operation
  [8] ATOMIC_TEST_AND_SWAP ro — PE can support an atomic test-and-swap operation
  [7] ATOMIC_INCRMNT ro — PE can support an atomic increment operation
  [6] ATOMIC_DCRMNT ro — PE can support an atomic decrement operation
  [5] ATOMIC_SET ro — PE can support an atomic set operation
  [4] ATOMIC_CLEAR ro — PE can support an atomic clear operation
  [2] PORT_WRITE ro — PE can support a port-write generation
  [1:0] IMPLMNT_DEFINED_1 ro — Defined by the device implementation
0x101C DEST_OP reset 0x4 — Destination Operations CAR
  fields as SRC_OP
